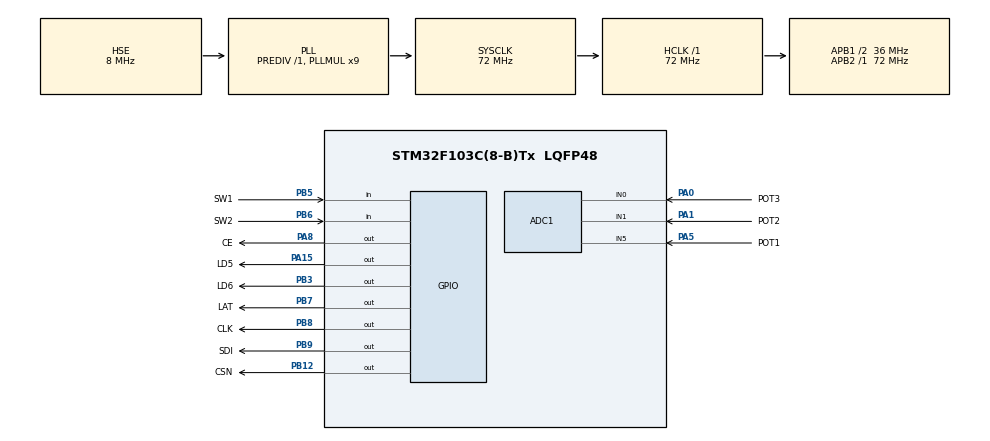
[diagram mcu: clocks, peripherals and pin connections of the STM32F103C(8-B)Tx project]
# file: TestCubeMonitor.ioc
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ADC1.Channel-0\#ChannelRegularConversion=ADC_CHANNEL_0
ADC1.Channel-1\#ChannelRegularConversion=ADC_CHANNEL_1
ADC1.Channel-2\#ChannelRegularConversion=ADC_CHANNEL_5
ADC1.ContinuousConvMode=ENABLE
ADC1.NbrOfConversion=3
ADC1.NbrOfConversionFlag=1
ADC1.Rank-0\#ChannelRegularConversion=1
ADC1.Rank-1\#ChannelRegularConversion=2
ADC1.Rank-2\#ChannelRegularConversion=3
ADC1.SamplingTime-0\#ChannelRegularConversion=ADC_SAMPLETIME_1CYCLE_5
ADC1.SamplingTime-1\#ChannelRegularConversion=ADC_SAMPLETIME_1CYCLE_5
ADC1.SamplingTime-2\#ChannelRegularConversion=ADC_SAMPLETIME_1CYCLE_5
ADC1.master=1
Dma.ADC1.0.Direction=DMA_PERIPH_TO_MEMORY
Dma.ADC1.0.Instance=DMA1_Channel1
Dma.ADC1.0.MemDataAlignment=DMA_MDATAALIGN_WORD
Dma.ADC1.0.MemInc=DMA_MINC_ENABLE
Dma.ADC1.0.Mode=DMA_CIRCULAR
Dma.ADC1.0.PeriphDataAlignment=DMA_PDATAALIGN_WORD
Dma.ADC1.0.PeriphInc=DMA_PINC_DISABLE
Dma.ADC1.0.Priority=DMA_PRIORITY_LOW
Dma.Request0=ADC1
Mcu.Family=STM32F1
Mcu.Name=STM32F103C(8-B)Tx
Mcu.Package=LQFP48
NVIC.DMA1_Channel1_IRQn=true\:0\:0\:false\:false\:true\:false\:true
NVIC.PriorityGroup=NVIC_PRIORITYGROUP_4
PA0-WKUP.GPIO_Label=POT3
PA0-WKUP.Signal=ADCx_IN0
PA1.GPIO_Label=POT2
PA1.Signal=ADCx_IN1
PA10.GPIO_Label=PWMC
PA10.Signal=S_TIM1_CH3
PA13.GPIO_Label=SWDIO
PA13.Mode=Serial_Wire
PA13.Signal=SYS_JTMS-SWDIO
PA14.GPIO_Label=SWCLK
PA14.Mode=Serial_Wire
PA14.Signal=SYS_JTCK-SWCLK
PA15.GPIO_Label=LD5
PA15.GPIO_ModeDefaultOutputPP=GPIO_MODE_OUTPUT_PP
PA15.GPIO_PuPd=GPIO_NOPULL
PA15.GPIO_Speed=GPIO_SPEED_FREQ_HIGH
PA15.PinState=GPIO_PIN_RESET
PA15.Signal=GPIO_Output
PA5.GPIO_Label=POT1
PA5.Signal=ADCx_IN5
PA6.GPIO_Label=Temp
PA6.Signal=ADCx_IN6
PA7.GPIO_Label=PWMG
PA7.Signal=S_TIM3_CH2
PA8.GPIO_Label=CE
PA8.GPIO_Speed=GPIO_SPEED_FREQ_HIGH
PA8.Signal=GPIO_Output
PA9.GPIO_Label=PWMS
PA9.Signal=S_TIM1_CH2
PB0.GPIO_Label=PWMB
PB0.Signal=S_TIM3_CH3
PB1.GPIO_Label=PWMR
PB1.Signal=S_TIM3_CH4
PB12.GPIO_Label=CSN
PB12.GPIO_Speed=GPIO_SPEED_FREQ_HIGH
PB12.Signal=GPIO_Output
PB13.GPIO_Label=SCK
PB13.Signal=SPI2_SCK
PB14.GPIO_Label=MISO
PB14.Signal=SPI2_MISO
PB15.GPIO_Label=MOSI
PB15.Signal=SPI2_MOSI
PB3.GPIO_Label=LD6
PB3.GPIO_ModeDefaultOutputPP=GPIO_MODE_OUTPUT_PP
PB3.GPIO_PuPd=GPIO_NOPULL
PB3.GPIO_Speed=GPIO_SPEED_FREQ_HIGH
PB3.PinState=GPIO_PIN_RESET
PB3.Signal=GPIO_Output
PB5.GPIO_Label=SW1
PB5.GPIO_Mode=GPIO_MODE_INPUT
PB5.GPIO_PuPd=GPIO_NOPULL
PB5.Signal=GPIO_Input
PB6.GPIO_Label=SW2
PB6.GPIO_Mode=GPIO_MODE_INPUT
PB6.GPIO_PuPd=GPIO_NOPULL
PB6.Signal=GPIO_Input
PB7.GPIO_Label=LAT
PB7.GPIO_ModeDefaultOutputPP=GPIO_MODE_OUTPUT_OD
PB7.GPIO_Speed=GPIO_SPEED_FREQ_HIGH
PB7.PinState=GPIO_PIN_RESET
PB7.Signal=GPIO_Output
PB8.GPIO_Label=CLK
PB8.GPIO_ModeDefaultOutputPP=GPIO_MODE_OUTPUT_OD
PB8.GPIO_Speed=GPIO_SPEED_FREQ_HIGH
PB8.PinState=GPIO_PIN_RESET
PB8.Signal=GPIO_Output
PB9.GPIO_Label=SDI
PB9.GPIO_ModeDefaultOutputPP=GPIO_MODE_OUTPUT_OD
PB9.GPIO_Speed=GPIO_SPEED_FREQ_HIGH
PB9.PinState=GPIO_PIN_RESET
PB9.Signal=GPIO_Output
PD0-OSC_IN.GPIO_Label=OSC_IN
PD0-OSC_IN.Mode=HSE-External-Oscillator
PD0-OSC_IN.Signal=RCC_OSC_IN
PD1-OSC_OUT.GPIO_Label=OSC_OUT
PD1-OSC_OUT.Mode=HSE-External-Oscillator
PD1-OSC_OUT.Signal=RCC_OSC_OUT
ProjectManager.HeapSize=0x200
ProjectManager.StackSize=0x400
ProjectManager.TargetToolchain=MDK-ARM V5.27
RCC.ADCPresc=RCC_ADCPCLK2_DIV6
RCC.AHBFreq_Value=72000000
RCC.APB1CLKDivider=RCC_HCLK_DIV2
RCC.APB1Freq_Value=36000000
RCC.APB1TimFreq_Value=72000000
RCC.APB2Freq_Value=72000000
RCC.APB2TimFreq_Value=72000000
RCC.HCLKFreq_Value=72000000
RCC.PLLMUL=RCC_PLL_MUL9
RCC.PLLSourceVirtual=RCC_PLLSOURCE_HSE
RCC.SYSCLKFreq_VALUE=72000000
RCC.SYSCLKSource=RCC_SYSCLKSOURCE_PLLCLK
RCC.USBFreq_Value=72000000
SH.ADCx_IN0.0=ADC1_IN0,IN0
SH.ADCx_IN1.0=ADC1_IN1,IN1
SH.ADCx_IN5.0=ADC1_IN5,IN5
SH.ADCx_IN6.0=ADC1_IN6
SH.S_TIM1_CH2.0=TIM1_CH2
SH.S_TIM1_CH3.0=TIM1_CH3
SH.S_TIM3_CH2.0=TIM3_CH2
SH.S_TIM3_CH3.0=TIM3_CH3
SH.S_TIM3_CH4.0=TIM3_CH4
board=custom

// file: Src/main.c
/* USER CODE BEGIN Header */
/**
  ******************************************************************************
  * @file           : main.c
  * @brief          : Main program body
  ******************************************************************************
  * @attention
  *
  * <h2><center>&copy; Copyright (c) 2020 STMicroelectronics.
  * All rights reserved.</center></h2>
  *
  * This software component is licensed by ST under BSD 3-Clause license,
  * the "License"; You may not use this file except in compliance with the
  * License. You may obtain a copy of the License at:
  *                        opensource.org/licenses/BSD-3-Clause
  *
  ******************************************************************************
  */
/* USER CODE END Header */

#include "main.h"
#include "adc.h"
#include "dma.h"
#include "gpio.h"

/* USER CODE BEGIN Includes */
#include "..\..\bsp\display.h"
/* USER CODE END Includes */

void SystemClock_Config(void);

/* USER CODE BEGIN 0 */
uint32_t Vals[3];
char Message[] = "helo";
void HAL_SYSTICK_Callback(void)
{
  DisplayString(Message);
  DisplayRun();
}
/* USER CODE END 0 */

int main(void)
{

  /* MCU Configuration--------------------------------------------------------*/

  /* Reset of all peripherals, Initializes the Flash interface and the Systick. */
  HAL_Init();

  /* Configure the system clock */
  SystemClock_Config();

  /* Initialize all configured peripherals */
  MX_GPIO_Init();
  MX_DMA_Init();
  MX_ADC1_Init();
  /* USER CODE BEGIN 2 */
  HAL_ADCEx_Calibration_Start(&hadc1);
  HAL_NVIC_DisableIRQ(DMA1_Channel1_IRQn);
  HAL_ADC_Start_DMA(&hadc1, Vals, 3);
  /* USER CODE END 2 */

  /* Infinite loop */
  while (1)
  {

  }
}

void SystemClock_Config(void)
{
  RCC_OscInitTypeDef RCC_OscInitStruct = {0};
  RCC_ClkInitTypeDef RCC_ClkInitStruct = {0};
  RCC_PeriphCLKInitTypeDef PeriphClkInit = {0};

  /** Initializes the CPU, AHB and APB busses clocks
  */
  RCC_OscInitStruct.OscillatorType = RCC_OSCILLATORTYPE_HSE;
  RCC_OscInitStruct.HSEState = RCC_HSE_ON;
  RCC_OscInitStruct.HSEPredivValue = RCC_HSE_PREDIV_DIV1;
  RCC_OscInitStruct.HSIState = RCC_HSI_ON;
  RCC_OscInitStruct.PLL.PLLState = RCC_PLL_ON;
  RCC_OscInitStruct.PLL.PLLSource = RCC_PLLSOURCE_HSE;
  RCC_OscInitStruct.PLL.PLLMUL = RCC_PLL_MUL9;
  if (HAL_RCC_OscConfig(&RCC_OscInitStruct) != HAL_OK)
  {
    Error_Handler();
  }
  /** Initializes the CPU, AHB and APB busses clocks
  */
  RCC_ClkInitStruct.ClockType = RCC_CLOCKTYPE_HCLK|RCC_CLOCKTYPE_SYSCLK
                              |RCC_CLOCKTYPE_PCLK1|RCC_CLOCKTYPE_PCLK2;
  RCC_ClkInitStruct.SYSCLKSource = RCC_SYSCLKSOURCE_PLLCLK;
  RCC_ClkInitStruct.AHBCLKDivider = RCC_SYSCLK_DIV1;
  RCC_ClkInitStruct.APB1CLKDivider = RCC_HCLK_DIV2;
  RCC_ClkInitStruct.APB2CLKDivider = RCC_HCLK_DIV1;

  if (HAL_RCC_ClockConfig(&RCC_ClkInitStruct, FLASH_LATENCY_2) != HAL_OK)
  {
    Error_Handler();
  }
  PeriphClkInit.PeriphClockSelection = RCC_PERIPHCLK_ADC;
  PeriphClkInit.AdcClockSelection = RCC_ADCPCLK2_DIV6;
  if (HAL_RCCEx_PeriphCLKConfig(&PeriphClkInit) != HAL_OK)
  {
    Error_Handler();
  }
}

void Error_Handler(void)
{
}

/************************ (C) COPYRIGHT STMicroelectronics *****END OF FILE****/
